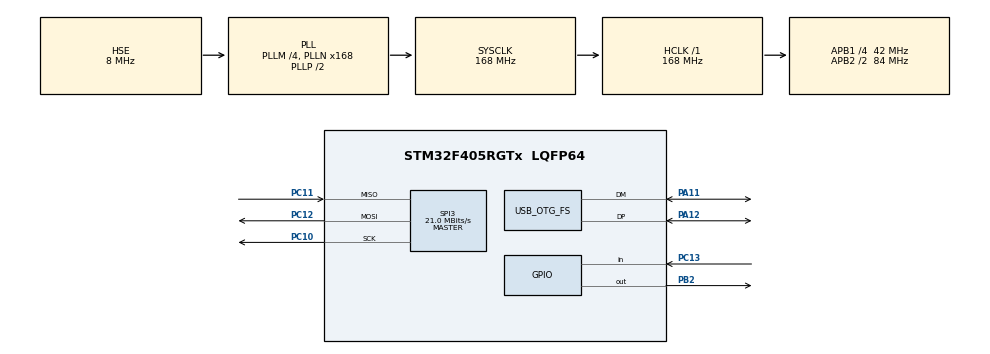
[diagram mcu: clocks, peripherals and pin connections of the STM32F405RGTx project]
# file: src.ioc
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Mcu.Family=STM32F4
Mcu.Name=STM32F405RGTx
Mcu.Package=LQFP64
NVIC.OTG_FS_IRQn=true\:0\:0\:false\:false\:true\:false\:true\:true
NVIC.PriorityGroup=NVIC_PRIORITYGROUP_4
PA11.Mode=Device_Only
PA11.Signal=USB_OTG_FS_DM
PA12.Mode=Device_Only
PA12.Signal=USB_OTG_FS_DP
PA13.Mode=Serial_Wire
PA13.Signal=SYS_JTMS-SWDIO
PA14.Mode=Serial_Wire
PA14.Signal=SYS_JTCK-SWCLK
PB2.Signal=GPIO_Output
PC10.Mode=Full_Duplex_Master
PC10.Signal=SPI3_SCK
PC11.Mode=Full_Duplex_Master
PC11.Signal=SPI3_MISO
PC12.Mode=Full_Duplex_Master
PC12.Signal=SPI3_MOSI
PC13-ANTI_TAMP.Signal=GPIO_Input
PC14-OSC32_IN.Mode=LSE-External-Oscillator
PC14-OSC32_IN.Signal=RCC_OSC32_IN
PC15-OSC32_OUT.Mode=LSE-External-Oscillator
PC15-OSC32_OUT.Signal=RCC_OSC32_OUT
PH0-OSC_IN.Mode=HSE-External-Oscillator
PH0-OSC_IN.Signal=RCC_OSC_IN
PH1-OSC_OUT.Mode=HSE-External-Oscillator
PH1-OSC_OUT.Signal=RCC_OSC_OUT
ProjectManager.HeapSize=0x200
ProjectManager.StackSize=0x400
ProjectManager.TargetToolchain=STM32CubeIDE
RCC.48MHZClocksFreq_Value=48000000
RCC.AHBFreq_Value=168000000
RCC.APB1CLKDivider=RCC_HCLK_DIV4
RCC.APB1Freq_Value=42000000
RCC.APB1TimFreq_Value=84000000
RCC.APB2CLKDivider=RCC_HCLK_DIV2
RCC.APB2Freq_Value=84000000
RCC.APB2TimFreq_Value=168000000
RCC.CortexFreq_Value=168000000
RCC.HCLKFreq_Value=168000000
RCC.HSE_VALUE=8000000
RCC.HSI_VALUE=16000000
RCC.PLLM=4
RCC.PLLN=168
RCC.PLLQ=7
RCC.SYSCLKFreq_VALUE=168000000
RCC.SYSCLKSource=RCC_SYSCLKSOURCE_PLLCLK
RCC.VCOOutputFreq_Value=336000000
SPI3.CalculateBaudRate=21.0 MBits/s
SPI3.Direction=SPI_DIRECTION_2LINES
SPI3.Mode=SPI_MODE_MASTER
SPI3.VirtualType=VM_MASTER
USB_DEVICE.CLASS_NAME_FS=CDC
USB_DEVICE.VirtualMode-CDC_FS=Cdc
USB_DEVICE.VirtualModeFS=Cdc_FS
USB_OTG_FS.VirtualMode=Device_Only
VP_USB_DEVICE_VS_USB_DEVICE_CDC_FS.Mode=CDC_FS
board=custom

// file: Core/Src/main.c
/* USER CODE BEGIN Header */
/**
  ******************************************************************************
  * @file           : main.c
  * @brief          : Main program body
  ******************************************************************************
  * @attention
  *
  * Copyright (c) 2025 STMicroelectronics.
  * All rights reserved.
  *
  * This software is licensed under terms that can be found in the LICENSE file
  * in the root directory of this software component.
  * If no LICENSE file comes with this software, it is provided AS-IS.
  *
  ******************************************************************************
  */
/* USER CODE END Header */
#include "main.h"
#include "usb_device.h"

/* USER CODE BEGIN Includes */
#include <stdio.h>
#include "usbd_cdc_if.h"
/* USER CODE END Includes */

SPI_HandleTypeDef hspi3;

/* USER CODE BEGIN PV */
int _write(int file, char *ptr, int len) {

    CDC_Transmit_FS((uint8_t *)ptr, len); // Transmit data over USB CDC
    return len; // Return the number of bytes written
}
/* USER CODE END PV */

void SystemClock_Config(void);
static void MX_GPIO_Init(void);
static void MX_SPI3_Init(void);

int main(void)
{

  /* MCU Configuration--------------------------------------------------------*/

  /* Reset of all peripherals, Initializes the Flash interface and the Systick. */
  HAL_Init();

  /* Configure the system clock */
  SystemClock_Config();

  /* Initialize all configured peripherals */
  MX_GPIO_Init();
  MX_SPI3_Init();
  MX_USB_DEVICE_Init();

  /* Infinite loop */
  /* USER CODE BEGIN WHILE */
  while (1)
  {
    HAL_GPIO_TogglePin(GPIOB, GPIO_PIN_2); // Toggle the LED on PB2
    printf("LED toggled! %d %d\r\n", HSE_VALUE, SystemCoreClock); // Print message to USB CDC
    HAL_Delay(1000); // Delay for 500 ms
    /* USER CODE END WHILE */

  }
}

void SystemClock_Config(void)
{
  RCC_OscInitTypeDef RCC_OscInitStruct = {0};
  RCC_ClkInitTypeDef RCC_ClkInitStruct = {0};

  /** Configure the main internal regulator output voltage
  */
  __HAL_RCC_PWR_CLK_ENABLE();
  __HAL_PWR_VOLTAGESCALING_CONFIG(PWR_REGULATOR_VOLTAGE_SCALE1);

  /** Initializes the RCC Oscillators according to the specified parameters
  * in the RCC_OscInitTypeDef structure.
  */
  RCC_OscInitStruct.OscillatorType = RCC_OSCILLATORTYPE_HSE;
  RCC_OscInitStruct.HSEState = RCC_HSE_ON;
  RCC_OscInitStruct.PLL.PLLState = RCC_PLL_ON;
  RCC_OscInitStruct.PLL.PLLSource = RCC_PLLSOURCE_HSE;
  RCC_OscInitStruct.PLL.PLLM = 4;
  RCC_OscInitStruct.PLL.PLLN = 168;
  RCC_OscInitStruct.PLL.PLLP = RCC_PLLP_DIV2;
  RCC_OscInitStruct.PLL.PLLQ = 7;
  if (HAL_RCC_OscConfig(&RCC_OscInitStruct) != HAL_OK)
  {
    Error_Handler();
  }

  /** Initializes the CPU, AHB and APB buses clocks
  */
  RCC_ClkInitStruct.ClockType = RCC_CLOCKTYPE_HCLK|RCC_CLOCKTYPE_SYSCLK
                              |RCC_CLOCKTYPE_PCLK1|RCC_CLOCKTYPE_PCLK2;
  RCC_ClkInitStruct.SYSCLKSource = RCC_SYSCLKSOURCE_PLLCLK;
  RCC_ClkInitStruct.AHBCLKDivider = RCC_SYSCLK_DIV1;
  RCC_ClkInitStruct.APB1CLKDivider = RCC_HCLK_DIV4;
  RCC_ClkInitStruct.APB2CLKDivider = RCC_HCLK_DIV2;

  if (HAL_RCC_ClockConfig(&RCC_ClkInitStruct, FLASH_LATENCY_5) != HAL_OK)
  {
    Error_Handler();
  }
}

static void MX_SPI3_Init(void)
{

  /* SPI3 parameter configuration*/
  hspi3.Instance = SPI3;
  hspi3.Init.Mode = SPI_MODE_MASTER;
  hspi3.Init.Direction = SPI_DIRECTION_2LINES;
  hspi3.Init.DataSize = SPI_DATASIZE_8BIT;
  hspi3.Init.CLKPolarity = SPI_POLARITY_LOW;
  hspi3.Init.CLKPhase = SPI_PHASE_1EDGE;
  hspi3.Init.NSS = SPI_NSS_SOFT;
  hspi3.Init.BaudRatePrescaler = SPI_BAUDRATEPRESCALER_2;
  hspi3.Init.FirstBit = SPI_FIRSTBIT_MSB;
  hspi3.Init.TIMode = SPI_TIMODE_DISABLE;
  hspi3.Init.CRCCalculation = SPI_CRCCALCULATION_DISABLE;
  hspi3.Init.CRCPolynomial = 10;
  if (HAL_SPI_Init(&hspi3) != HAL_OK)
  {
    Error_Handler();
  }

}

static void MX_GPIO_Init(void)
{
  GPIO_InitTypeDef GPIO_InitStruct = {0};

  /* GPIO Ports Clock Enable */
  __HAL_RCC_GPIOC_CLK_ENABLE();
  __HAL_RCC_GPIOH_CLK_ENABLE();
  __HAL_RCC_GPIOB_CLK_ENABLE();
  __HAL_RCC_GPIOA_CLK_ENABLE();

  /*Configure GPIO pin Output Level */
  HAL_GPIO_WritePin(GPIOB, GPIO_PIN_2, GPIO_PIN_RESET);

  /*Configure GPIO pin : PC13 */
  GPIO_InitStruct.Pin = GPIO_PIN_13;
  GPIO_InitStruct.Mode = GPIO_MODE_INPUT;
  GPIO_InitStruct.Pull = GPIO_NOPULL;
  HAL_GPIO_Init(GPIOC, &GPIO_InitStruct);

  /*Configure GPIO pin : PB2 */
  GPIO_InitStruct.Pin = GPIO_PIN_2;
  GPIO_InitStruct.Mode = GPIO_MODE_OUTPUT_PP;
  GPIO_InitStruct.Pull = GPIO_NOPULL;
  GPIO_InitStruct.Speed = GPIO_SPEED_FREQ_LOW;
  HAL_GPIO_Init(GPIOB, &GPIO_InitStruct);

}

void Error_Handler(void)
{
  __disable_irq();
  while (1)
  {
  }
}
